# AE402FA0E5597BE0_CM55_HP_View register map
Vendor: Alif Semiconductor; Series: E4; File version: 1.0
CPU: CM55 r1p0, selectable endian, MPU, FPU, double-precision FPU, DSP, VTOR, 8 interrupt priority bits, 1 SAU regions
Registers are 32-bit, read-write, reset 0x0 unless marked. A register's access mark holds for its fields unless they carry their own. Offsets are from the block's base; [hi:lo] are bit positions; lines under a group give offsets from that group; {n}, {i} and the like mark numbered series.

## REFCLK_CNTCtl
Base 0x1A220000
Same registers: S32K_CNTCtl 0x1A420000
0x00 CNTFRQ reset not defined — Counter Frequency Register
  [31:0] CLK_FREQ — Indicates the counter clock frequency in Hz. This field must be programmed with the counter clock frequency value as part of system initialization. The value of this field is not interpreted by hardware. Note: This register is accessed only by SE.
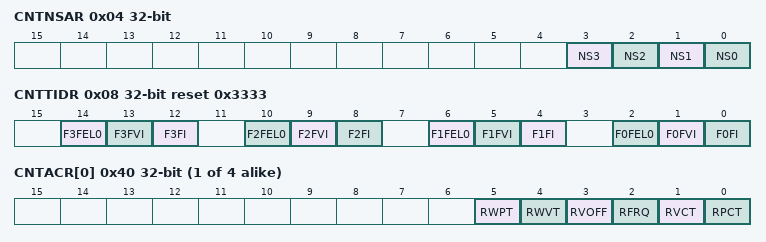
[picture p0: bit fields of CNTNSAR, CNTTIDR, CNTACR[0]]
0x04 CNTNSAR (reset mask 0xFFFFFFF0) — Counter Non-Secure Access Register
  [all] fields
    0=Secure access only permitted; 1=Secure and Non-secure accesses permitted
  [3] NS3 — Non-secure access permission to registers CNTACR3, CNTVOFF3_LO, CNTVOFF3_HI, and the registers from CNT_BASE3. Note: This bit is not available for S32KCLK_CNT_CTL.
  [2] NS2 — Non-secure access permission to registers CNTACR2, CNTVOFF2_LO, CNTVOFF2_HI, and the registers from CNT_BASE2. Note: This bit is not available for S32KCLK_CNT_CTL.
  [1] NS1 — Non-secure access permission to registers CNTACR1, CNTVOFF1_LO, CNTVOFF1_HI, and the registers from CNT_BASE1.
  [0] NS0 — Non-secure access permission to registers CNTACR0, CNTVOFF0_LO, CNTVOFF0_HI, and the registers from CNT_BASE0.
0x08 CNTTIDR ro reset 0x3333 — Counter Timer ID Register
  [14] F3FEL0 — CNT_BASE3 privileged view indicator. Note: This bit is not available for S32KCLK_CNT_CTL.
    0=CNT_BASE3 has only privileged view; 1=CNT_BASE3 has both privileged and unprivileged views
  [13] F3FVI — CNT_BASE3 virtual capability indicator. Note: This bit is not available for S32KCLK_CNT_CTL.
    0=CNT_BASE3 does not have virtual capability; 1=CNT_BASE3 has virtual capability
  [12] F3FI — CNT_BASE3 availability indicator. Note: This bit is not available for S32KCLK_CNT_CTL.
    0=CNT_BASE3 is not implemented; 1=CNT_BASE3 is implemented
  [10] F2FEL0 — CNT_BASE2 privileged view indicator. Note: This bit is not available for S32KCLK_CNT_CTL.
    0=CNT_BASE2 has only privileged view; 1=CNT_BASE2 has both privileged and unprivileged views
  [9] F2FVI — CNT_BASE2 virtual capability indicator. Note: This bit is not available for S32KCLK_CNT_CTL.
    0=CNT_BASE2 does not have virtual capability; 1=CNT_BASE2 has virtual capability
  [8] F2FI — CNT_BASE2 availability indicator. Note: This bit is not available for S32KCLK_CNT_CTL.
    0=CNT_BASE2 is not implemented; 1=CNT_BASE2 is implemented
  [6] F1FEL0 — CNT_BASE1 privileged view indicator.
    0=CNT_BASE1 has only privileged view; 1=CNT_BASE1 has both privileged and unprivileged views
  [5] F1FVI — CNT_BASE1 virtual capability indicator.
    0=CNT_BASE1 does not have virtual capability; 1=CNT_BASE1 has virtual capability
  [4] F1FI — CNT_BASE1 availability indicator.
    0=CNT_BASE1 is not implemented; 1=CNT_BASE1 is implemented
  [2] F0FEL0 — CNT_BASE0 privileged view indicator.
    0=CNT_BASE0 has only privileged view; 1=CNT_BASE0 has both privileged and unprivileged views
  [1] F0FVI — CNT_BASE0 virtual capability indicator.
    0=CNT_BASE0 does not have virtual capability; 1=CNT_BASE0 has virtual capability
  [0] F0FI — CNT_BASE0 availability indicator.
    0=CNT_BASE0 is not implemented; 1=CNT_BASE0 is implemented
{0x40+4i} CNTACR[{i}] (i=0..3) (reset mask 0xFFFFFFC0) — CNT_BASEn Access Control Register
  [5] RWPT — Read-write access control for registers CNTP_CVAL_LO, CNTP_CVAL_HI, CNTP_TVAL, and CNTP_CTL
    1=Read-write access allowed
  [4] RWVT — Read-write access control for registers CNTV_CVAL_LO, CNTV_CVAL_HI, CNTV_TVAL, and CNTV_CTL
    1=Read-write access allowed
  [3] RVOFF — Read-only access control for registers CNTVOFF_LO, and CNTVOFF_HI
    1=Read-only access allowed
  [2] RFRQ — Read-only access control for register RD_CNTFRQ
    1=Read-only access allowed
  [1] RVCT — Read-only access control for registers CNTVCT_LO, and CNTVCT_HI
    1=Read-only access allowed
  [0] RPCT — Read-only access control for registers CNTPCT_LO, and CNTPCT_HI
    1=Read-only access allowed
{0x80+8i} CNT_BASE_VOFF[{i}] (i=0..3) group
  0x00 CNTVOFF_LO reset not defined — CNT_BASEn Virtual Offset Low Register
    [31:0] VIRT_OFFSET_LO — Bits [31:0] of the virtual offset value for CNT_BASEn. This field is the read-write version of the CNTVOFF_LO. This is the offset between real time and virtual time.
  0x04 CNTVOFF_HI reset not defined — CNT_BASEn Virtual Offset High Register
    [31:0] VIRT_OFFSET_HI — Bits [63:32] of the virtual offset value for CNT_BASEn. This field is the read-write version of the CNTVOFF_HI. This is the offset between real time and virtual time.
